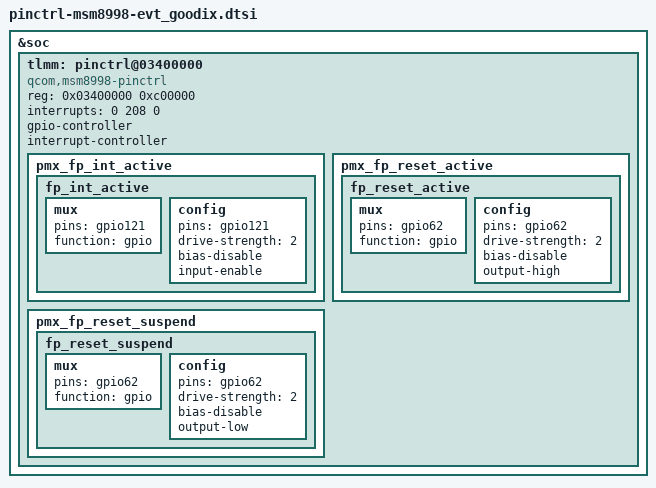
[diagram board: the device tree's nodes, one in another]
/* Copyright (c) 2015-2016, The Linux Foundation. All rights reserved.
 *
 * This program is free software; you can redistribute it and/or modify
 * it under the terms of the GNU General Public License version 2 and
 * only version 2 as published by the Free Software Foundation.
 *
 * This program is distributed in the hope that it will be useful,
 * but WITHOUT ANY WARRANTY; without even the implied warranty of
 * MERCHANTABILITY or FITNESS FOR A PARTICULAR PURPOSE.  See the
 * GNU General Public License for more details.
 */

&soc {
	tlmm: pinctrl@03400000 {
		compatible = "qcom,msm8998-pinctrl";
		reg = <0x03400000 0xc00000>;
		interrupts = <0 208 0>;
		gpio-controller;
		#gpio-cells = <2>;
		interrupt-controller;
		#interrupt-cells = <2>;


/*KC add for fingerprint start*/
		pmx_fp_int_active {
			fp_int_active: fp_int_active {
				mux {
					pins = "gpio121";
					function = "gpio";
				};

				config {
					pins = "gpio121";
					drive-strength = <2>;
					bias-disable;
					input-enable;
				};
			};
		};

		pmx_fp_reset_active {
			fp_reset_active: fp_reset_active {
				mux {
					pins = "gpio62";
					function = "gpio";
				};

				config {
					pins = "gpio62";
					drive-strength = <2>;
					bias-disable;
					output-high;
				};
			};
		};

		pmx_fp_reset_suspend {
			fp_reset_suspend: fp_reset_suspend {
				mux {
					pins = "gpio62";
					function = "gpio";
				};

				config {
					pins = "gpio62";
					drive-strength = <2>;
					bias-disable;
					output-low;
				};
			};
		};
/*KC add for fingerprint end*/

	};
};
